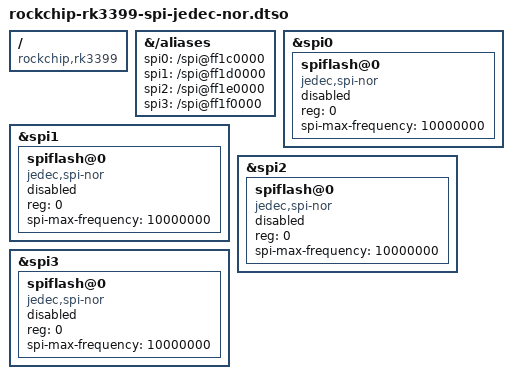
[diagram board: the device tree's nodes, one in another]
/dts-v1/;
/plugin/;

/ {
	compatible = "rockchip,rk3399";

	fragment@0 {
		target-path = "/aliases";
		__overlay__ {
			spi0 = "/spi@ff1c0000";
			spi1 = "/spi@ff1d0000";
			spi2 = "/spi@ff1e0000";
			spi3 = "/spi@ff1f0000";
		};
	};

	fragment@1 {
		target = <&spi0>;
		__overlay__ {
			#address-cells = <1>;
			#size-cells = <0>;
			spiflash@0 {
				compatible = "jedec,spi-nor";
				reg = <0>;
				spi-max-frequency = <10000000>;
				status = "disabled";
			};
		};
	};

	fragment@2 {
		target = <&spi1>;
		__overlay__ {
			#address-cells = <1>;
			#size-cells = <0>;
			spiflash@0 {
				compatible = "jedec,spi-nor";
				reg = <0>;
				spi-max-frequency = <10000000>;
				status = "disabled";
			};
		};
	};

	fragment@3 {
		target = <&spi2>;
		__overlay__ {
			#address-cells = <1>;
			#size-cells = <0>;
			spiflash@0 {
				compatible = "jedec,spi-nor";
				reg = <0>;
				spi-max-frequency = <10000000>;
				status = "disabled";
			};
		};
	};

	fragment@4 {
		target = <&spi3>;
		__overlay__ {
			#address-cells = <1>;
			#size-cells = <0>;
			spiflash@0 {
				compatible = "jedec,spi-nor";
				reg = <0>;
				spi-max-frequency = <10000000>;
				status = "disabled";
			};
		};
	};
};
